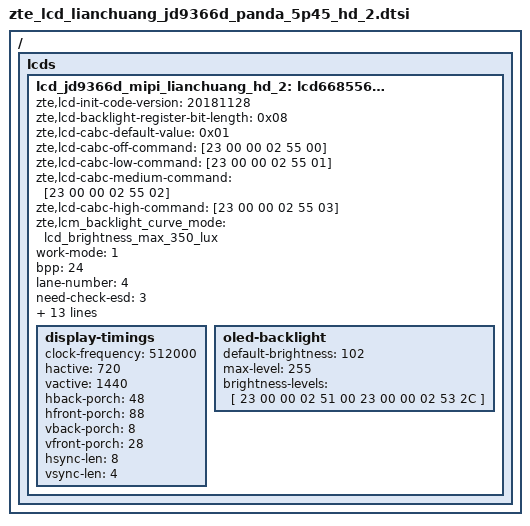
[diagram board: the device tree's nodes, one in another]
/ { lcds {
	lcd_jd9366d_mipi_lianchuang_hd_2: lcd668556@668556 {
		zte,lcd-init-code-version = "20181128";
		zte,lcd-backlight-register-bit-length = <0x08>;
		zte,lcd-cabc-default-value = <0x01>;
		zte,lcd-cabc-off-command = [23 00 00 02 55 00];
		zte,lcd-cabc-low-command = [23 00 00 02 55 01];
		zte,lcd-cabc-medium-command = [23 00 00 02 55 02];
		zte,lcd-cabc-high-command = [23 00 00 02 55 03];
		zte,lcm_backlight_curve_mode = "lcd_brightness_max_350_lux";

		work-mode = <1>;
		bpp = <24>;
		lane-number = <4>;

		need-check-esd = <3>;
		esd-timeout = <2000>;

		fps = <60>;
		width-mm = <62>;
		height-mm = <123>;
		panel-name = "lcd_jd9366d_mipi_lianchuang_hd";

		power-on-sequence = <
					62  1  6
					4   1  5
					5   1  10
					50  1  5
					50  0  2
					50  1  10
					>;
		power-off-sequence = <
					50  1  20
					5   0	5
					4   0   5
					>;

		init-data = [
39 00 00 02 e0 00
39 00 00 02 e1 93
39 00 00 02 e2 66
39 00 00 02 e3 f9
39 00 00 02 80 03
39 00 00 02 e0 01
39 00 00 02 00 01
39 00 00 02 01 23
39 00 00 02 03 01
39 00 00 02 04 23
39 00 00 02 0a 08
39 00 00 02 13 00
39 00 00 02 14 99
39 00 00 02 17 00
39 00 00 02 18 8F
39 00 00 02 19 01
39 00 00 02 1a 00
39 00 00 02 1b 8F
39 00 00 02 1c 01
39 00 00 02 1f 2f
39 00 00 02 20 2d
39 00 00 02 21 19
39 00 00 02 22 0d
39 00 00 02 23 02
39 00 00 02 24 fe
39 00 00 02 26 df
39 00 00 02 35 13
39 00 00 02 37 09
39 00 00 02 38 04
39 00 00 02 39 01
39 00 00 02 3a 03
39 00 00 02 3c 60
39 00 00 02 3d 18
39 00 00 02 3e 80
39 00 00 02 3f 4e
39 00 00 02 3d ff
39 00 00 02 3e ff
39 00 00 02 3f ff
39 00 00 02 4b 04
39 00 00 02 40 04
39 00 00 02 41 b4
39 00 00 02 42 70
39 00 00 02 43 24
39 00 00 02 44 0c
39 00 00 02 45 64
39 00 00 02 55 05
39 00 00 02 56 01
39 00 00 02 57 6d
39 00 00 02 58 0a
39 00 00 02 59 8a
39 00 00 02 5a 28
39 00 00 02 5b 23
39 00 00 02 5c 15
39 00 00 02 5d 73
39 00 00 02 5e 58
39 00 00 02 5f 49
39 00 00 02 60 3D
39 00 00 02 61 3A
39 00 00 02 62 2B
39 00 00 02 63 30
39 00 00 02 64 19
39 00 00 02 65 31
39 00 00 02 66 30
39 00 00 02 67 30
39 00 00 02 68 4F
39 00 00 02 69 3E
39 00 00 02 6a 47
39 00 00 02 6b 39
39 00 00 02 6c 35
39 00 00 02 6d 28
39 00 00 02 6e 16
39 00 00 02 6f 00
39 00 00 02 70 73
39 00 00 02 71 58
39 00 00 02 72 49
39 00 00 02 73 3D
39 00 00 02 74 3A
39 00 00 02 75 2B
39 00 00 02 76 30
39 00 00 02 77 19
39 00 00 02 78 31
39 00 00 02 79 30
39 00 00 02 7a 30
39 00 00 02 7b 4F
39 00 00 02 7c 3E
39 00 00 02 7d 47
39 00 00 02 7e 39
39 00 00 02 7f 35
39 00 00 02 80 28
39 00 00 02 81 16
39 00 00 02 82 00
39 00 00 02 e0 02
39 00 00 02 00 5d
39 00 00 02 01 51
39 00 00 02 02 5d
39 00 00 02 03 5d
39 00 00 02 04 5e
39 00 00 02 05 5f
39 00 00 02 06 51
39 00 00 02 07 41
39 00 00 02 08 45
39 00 00 02 09 5d
39 00 00 02 0a 5d
39 00 00 02 0b 4b
39 00 00 02 0c 49
39 00 00 02 0d 5d
39 00 00 02 0e 5d
39 00 00 02 0f 47
39 00 00 02 10 5f
39 00 00 02 11 5d
39 00 00 02 12 5d
39 00 00 02 13 5d
39 00 00 02 14 5d
39 00 00 02 15 5d
39 00 00 02 16 5d
39 00 00 02 17 50
39 00 00 02 18 5d
39 00 00 02 19 5d
39 00 00 02 1a 5e
39 00 00 02 1b 5f
39 00 00 02 1c 50
39 00 00 02 1d 40
39 00 00 02 1e 44
39 00 00 02 1f 5d
39 00 00 02 20 5d
39 00 00 02 21 4a
39 00 00 02 22 48
39 00 00 02 23 5d
39 00 00 02 24 5d
39 00 00 02 25 46
39 00 00 02 26 5f
39 00 00 02 27 5d
39 00 00 02 28 5d
39 00 00 02 29 5d
39 00 00 02 2a 5d
39 00 00 02 2b 5d
39 00 00 02 2c 1d
39 00 00 02 2d 10
39 00 00 02 2e 1d
39 00 00 02 2f 1d
39 00 00 02 30 1f
39 00 00 02 31 1e
39 00 00 02 32 00
39 00 00 02 33 10
39 00 00 02 34 06
39 00 00 02 35 1d
39 00 00 02 36 1d
39 00 00 02 37 08
39 00 00 02 38 0a
39 00 00 02 39 1d
39 00 00 02 3a 1d
39 00 00 02 3b 04
39 00 00 02 3c 1f
39 00 00 02 3d 1d
39 00 00 02 3e 1d
39 00 00 02 3f 1d
39 00 00 02 40 1d
39 00 00 02 41 1d
39 00 00 02 42 1d
39 00 00 02 43 11
39 00 00 02 44 1d
39 00 00 02 45 1d
39 00 00 02 46 1f
39 00 00 02 47 1e
39 00 00 02 48 01
39 00 00 02 49 11
39 00 00 02 4a 07
39 00 00 02 4b 1d
39 00 00 02 4c 1d
39 00 00 02 4d 09
39 00 00 02 4e 0b
39 00 00 02 4f 1d
39 00 00 02 50 1d
39 00 00 02 51 05
39 00 00 02 52 1f
39 00 00 02 53 1d
39 00 00 02 54 1d
39 00 00 02 55 1d
39 00 00 02 56 1d
39 00 00 02 57 1d
39 00 00 02 58 41
39 00 00 02 59 00
39 00 00 02 5a 00
39 00 00 02 5b 10
39 00 00 02 5c 02
39 00 00 02 5d 60
39 00 00 02 5e 01
39 00 00 02 5f 02
39 00 00 02 60 40
39 00 00 02 61 03
39 00 00 02 62 04
39 00 00 02 63 14
39 00 00 02 64 1a
39 00 00 02 65 55
39 00 00 02 66 b1
39 00 00 02 67 73
39 00 00 02 68 04
39 00 00 02 69 16
39 00 00 02 6a 52
39 00 00 02 6b 0a
39 00 00 02 6c 00
39 00 00 02 6d 00
39 00 00 02 6e 00
39 00 00 02 6f 88
39 00 00 02 70 00
39 00 00 02 71 00
39 00 00 02 72 06
39 00 00 02 73 7b
39 00 00 02 74 00
39 00 00 02 75 bc
39 00 00 02 76 00
39 00 00 02 77 05
39 00 00 02 78 34
39 00 00 02 79 00
39 00 00 02 7a 00
39 00 00 02 7b 00
39 00 00 02 7c 00
39 00 00 02 7d 03
39 00 00 02 7e 7b
39 00 00 02 80 06
39 00 00 02 93 4D
39 00 00 02 e0 04
39 00 00 02 00 02
39 00 00 02 02 23
39 00 00 02 03 8f
39 00 00 02 09 11
39 00 00 02 0e 2a
39 00 00 02 96 0a
39 00 00 02 9a 01
39 00 00 02 9b 15
39 00 00 02 a9 01
39 00 00 02 aa 68
39 00 00 02 ac 19
39 00 00 02 ad 0d
39 00 00 02 ae 0d
39 00 00 02 e0 05
39 00 00 02 13 33
39 00 00 02 e0 00
39 00 00 02 e6 02
39 00 00 02 e7 06
39 00 00 02 e0 03
39 00 00 02 9a 01
39 00 00 02 9b 00
39 00 00 02 e0 00
39 00 00 02 35 00
39 00 00 02 51 00
39 00 00 02 53 24
39 00 00 02 55 01
39 00 00 02 5e 03
13 78 00 01 11
13 20 00 01 29
			];
		sleep-in = [
			23 00 00 02 53 00
			23 32 00 02 E0 00
			23 00 00 02 E0 00
			23 00 00 02 E7 16
			13 10 00 01 28
			13 F0 00 01 10
			];
		sleep-out = [
			13 78 00 01 11
			13 64 00 01 29
			];

		display-timings {
			clock-frequency = <512000>;
			hactive = <720>;
			vactive = <1440>;
			hback-porch = <48>;
			hfront-porch = <88>;
			vback-porch = <8>;
			vfront-porch = <28>;
			hsync-len = <8>;
			vsync-len = <4>;
		};
		oled-backlight {
			default-brightness = <102>;
			max-level = <255>;
			brightness-levels = [
				23 00 00 02 51 00
				23 00 00 02 53 2C
			];
		};
	};
};};

